# va416xx register map
Vendor: VORAGO TECHNOLOGIES; Series: M4; File version: 1.3
CPU: CM4 r0p1, little endian, no MPU, FPU, 4 interrupt priority bits
Registers are 32-bit, read-write, reset 0x0 unless marked. A register's access mark holds for its fields unless they carry their own. Offsets are from the block's base; [hi:lo] are bit positions; {n}, {i} and the like mark numbered series.

## DMA — DMA Controller Block
Base 0x40001000
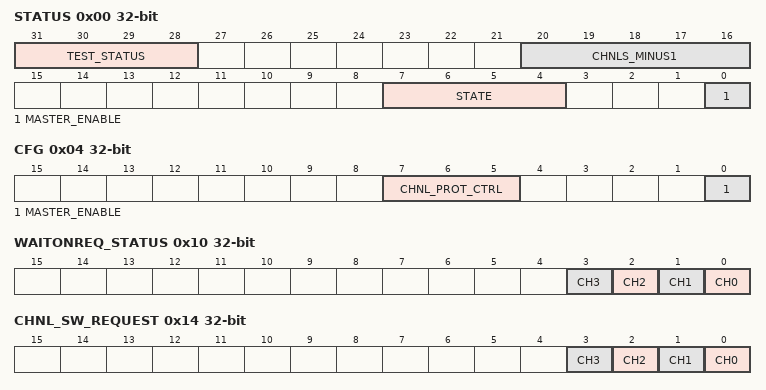
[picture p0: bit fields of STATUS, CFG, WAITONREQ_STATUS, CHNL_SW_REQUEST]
0x00 STATUS ro — DMA Status
  [31:28] TEST_STATUS rw — Test Status Logic Included
  [20:16] CHNLS_MINUS1 — Number of Available Channels Minus 1
  [7:4] STATE — Current State of the control state machine
  [0] MASTER_ENABLE — Enable status of the controller
0x04 CFG wo — DMA Configuration
  [7:5] CHNL_PROT_CTRL — HPROT[3:0]
  [0] MASTER_ENABLE ro — PLL Symbol; Feedback cycle slip output (CLKOUT frequency low)
0x08 CTRL_BASE_PTR — Base Pointer for DMA Control Registers
  [31:7] CTRL_BASE_PTR
0x0C ALT_CTRL_BASE_PTR — DMA Channel alternate control data base pointer
  [31:0] ALT_CTRL_BASE_PTR — Base Pointer for Alternate DMA Control Register
0x10 WAITONREQ_STATUS ro — DMA channel wait on request status
  [n] CH{n} rw (n=0..3) — DMA wait on request
0x14 CHNL_SW_REQUEST wo — DMA channel software request
  [n] CH{n} rw (n=0..3) — Channel SW request
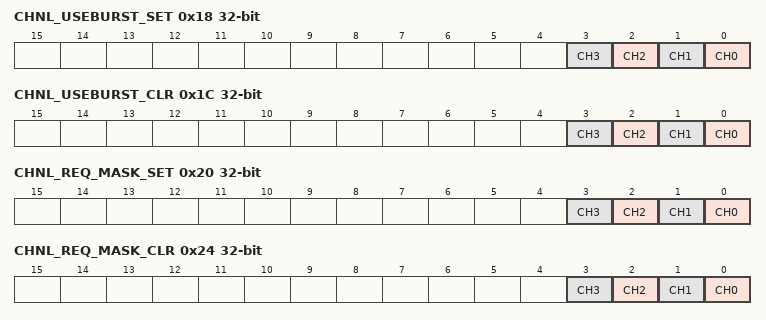
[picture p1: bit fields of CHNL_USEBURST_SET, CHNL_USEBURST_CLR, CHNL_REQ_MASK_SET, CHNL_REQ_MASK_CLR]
0x18 CHNL_USEBURST_SET — DMA channel useburst set
  [n] CH{n} (n=0..3) — Channel use burst set
0x1C CHNL_USEBURST_CLR — DMA channel useburst clear
  [n] CH{n} (n=0..3) — Channel use burst clear
0x20 CHNL_REQ_MASK_SET — DMA channel request mask set
  [n] CH{n} (n=0..3) — Channel Request Mask set
0x24 CHNL_REQ_MASK_CLR — DMA channel request mask clear
  [n] CH{n} (n=0..3) — Channel Request Mask clear
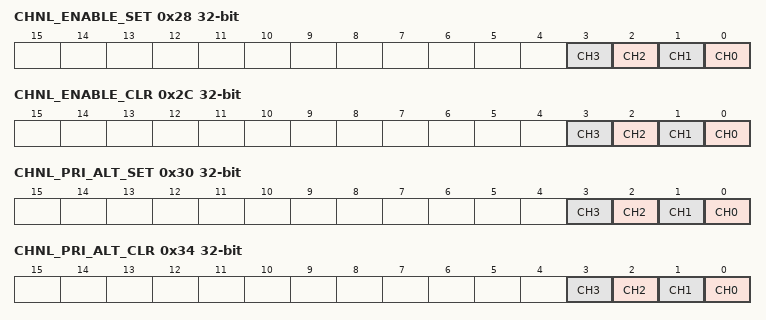
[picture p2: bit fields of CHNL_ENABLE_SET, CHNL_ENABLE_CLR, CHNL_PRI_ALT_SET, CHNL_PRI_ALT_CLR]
0x28 CHNL_ENABLE_SET — DMA channel enable set
  [n] CH{n} (n=0..3) — Channel Enable set
0x2C CHNL_ENABLE_CLR — DMA channel enable clear
  [n] CH{n} (n=0..3) — Channel Enable clear
0x30 CHNL_PRI_ALT_SET — DMA channel primary alternate set
  [n] CH{n} (n=0..3) — Channel PRI_ALT set
0x34 CHNL_PRI_ALT_CLR — DMA channel primary alternate clear
  [n] CH{n} (n=0..3) — Channel PRI_ALT clear
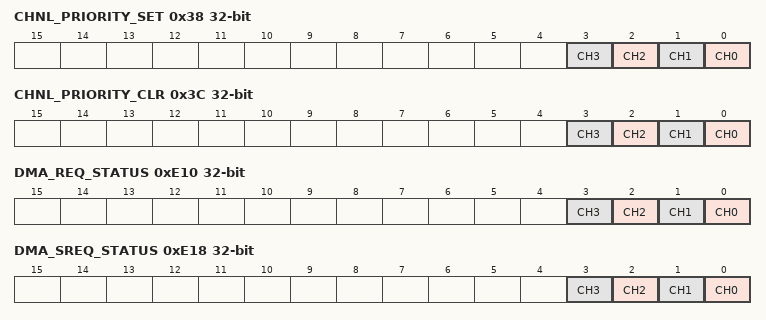
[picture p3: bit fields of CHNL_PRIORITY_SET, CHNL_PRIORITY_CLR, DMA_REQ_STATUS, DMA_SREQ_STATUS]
0x38 CHNL_PRIORITY_SET — DMA channel priority set
  [n] CH{n} (n=0..3) — Channel PRIORITY set
0x3C CHNL_PRIORITY_CLR wo — DMA channel priority clear
  [n] CH{n} (n=0..3) — Channel PRIORITY clear
0x4C ERR_CLR — DMA bus error clear
  [0] ERR_CLR — Error Clear
0xE00 INTEGRATION_CFG — DMA integration configuration
  [0] INT_TEST_EN — Error Clear
0xE08 STALL_STATUS — DMA stall status
  [0] STALL_STATUS ro — DMA is stalled
0xE10 DMA_REQ_STATUS — DMA Configuration
  [n] CH{n} (n=0..3) — DMA Request Status for this CH
0xE18 DMA_SREQ_STATUS — DMA single request status
  [n] CH{n} (n=0..3) — DMA SRequest Status for this CH
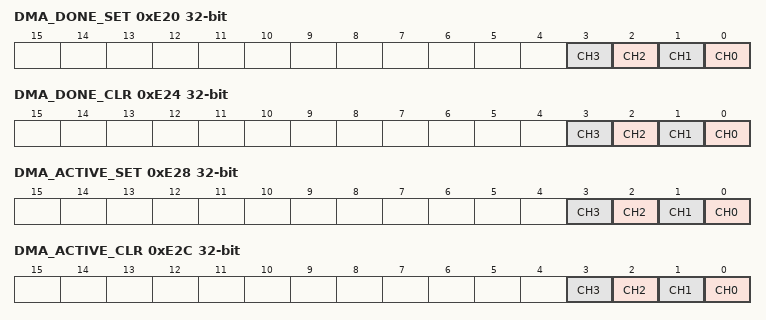
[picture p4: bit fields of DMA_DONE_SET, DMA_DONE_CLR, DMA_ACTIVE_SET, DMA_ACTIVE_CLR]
0xE20 DMA_DONE_SET
  [n] CH{n} (n=0..3) — DMA Done Set for this CH
0xE24 DMA_DONE_CLR — DMA done clear
  [n] CH{n} (n=0..3) — DMA Done clear for this CH
0xE28 DMA_ACTIVE_SET
  [n] CH{n} (n=0..3) — DMA Active Set
0xE2C DMA_ACTIVE_CLR — DMA active clear
  [n] CH{n} (n=0..3) — DMA Active clear
0xE48 ERR_SET — DMA bus error set
  [0] ERR_SET ro — Set Error
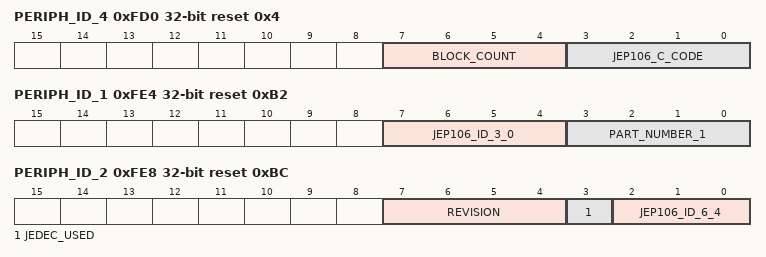
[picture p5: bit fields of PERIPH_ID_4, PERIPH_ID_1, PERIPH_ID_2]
0xFD0 PERIPH_ID_4 reset 0x4 — DMA Peripheral ID 4
  [7:4] BLOCK_COUNT — The Number of 4k Address Blocks Required
  [3:0] JEP106_C_CODE — JEP106
0xFE0 PERIPH_ID_0 reset 0x30 — DMA Peripheral ID 0
  [7:0] PART_NUMBER_0 — Part Number
0xFE4 PERIPH_ID_1 ro reset 0xB2 — DMA Peripheral ID 1
  [7:4] JEP106_ID_3_0 — Indentity Code
  [3:0] PART_NUMBER_1
0xFE8 PERIPH_ID_2 reset 0xBC — DMA Peripheral ID 2
  [7:4] REVISION
  [3] JEDEC_USED — JEDEC
  [2:0] JEP106_ID_6_4 — JEP106
0xFEC PERIPH_ID_3 — DMA Peripheral ID 3
  [3:0] MOD_NUMBER — Controller Modifications
0xFF0 PRIMECELL_ID_0 reset 0xD — DMA PrimeCell ID 0
  [7:0] PRIMECELL_ID_0 — PrimeCell Identification
0xFF4 PRIMECELL_ID_1 reset 0xF0 — DMA PrimeCell ID 1
  [7:0] PRIMECELL_ID_1 — PrimeCell Identification
0xFF8 PRIMECELL_ID_2 reset 0x5 — DMA PrimeCell ID 2
  [7:0] PRIMECELL_ID_2 — PrimeCell Identification
0xFFC PRIMECELL_ID_3 reset 0xB1 — DMA PrimeCell ID 3
  [7:0] PRIMECELL_ID_3 — PrimeCell Identification
